VERSION ""

NS_ :

BS_:

BU_: Tester RearECU MyECU

BO_ 3221225472 VECTOR__INDEPENDENT_SIG_MSG: 0 Vector__XXX
 SG_ Signal_TxMulti_Stat : 0|5@1+ (1,0) [0|31] "" Vector__XXX
 SG_ SigTx_Prof1C_DataId_LoByte : 0|8@1+ (1,0) [0|255] "" Vector__XXX
 SG_ SigRx_Prof1C_DataId_LoByte : 0|8@1+ (1,0) [0|255] "" Vector__XXX

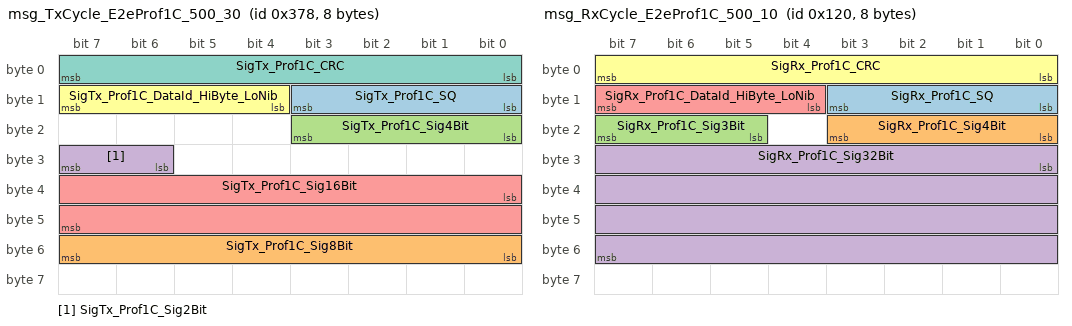
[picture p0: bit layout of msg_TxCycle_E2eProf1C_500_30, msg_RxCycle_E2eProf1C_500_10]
BO_ 888 msg_TxCycle_E2eProf1C_500_30: 8 MyECU
 SG_ SigTx_Prof1C_SQ : 8|4@1+ (1,0) [0|15] ""  RearECU
 SG_ SigTx_Prof1C_Sig8Bit : 48|8@1+ (1,0) [0|255] ""  RearECU
 SG_ SigTx_Prof1C_Sig4Bit : 16|4@1+ (1,0) [0|15] ""  RearECU
 SG_ SigTx_Prof1C_Sig2Bit : 30|2@1+ (1,0) [0|3] ""  RearECU
 SG_ SigTx_Prof1C_Sig16Bit : 32|16@1+ (1,0) [0|65535] ""  RearECU
 SG_ SigTx_Prof1C_DataId_HiByte_LoNib : 12|4@1+ (1,0) [0|15] ""  RearECU
 SG_ SigTx_Prof1C_CRC : 0|8@1+ (1,0) [0|255] ""  RearECU

BO_ 288 msg_RxCycle_E2eProf1C_500_10: 8 RearECU
 SG_ SigRx_Prof1C_SQ : 8|4@1+ (1,0) [0|15] ""  MyECU
 SG_ SigRx_Prof1C_Sig4Bit : 16|4@1+ (1,0) [0|15] ""  MyECU
 SG_ SigRx_Prof1C_Sig3Bit : 21|3@1+ (1,0) [0|7] ""  MyECU
 SG_ SigRx_Prof1C_Sig32Bit : 24|32@1+ (1,0) [0|4294967295] ""  MyECU
 SG_ SigRx_Prof1C_DataId_HiByte_LoNib : 12|4@1+ (1,0) [0|15] ""  MyECU
 SG_ SigRx_Prof1C_CRC : 0|8@1+ (1,0) [0|255] ""  MyECU

BO_ 512 msg_TxCycle100_20: 8 MyECU
 SG_ Signal_SwitchRearInteriorLight : 0|8@1+ (1,0) [0|255] ""  RearECU

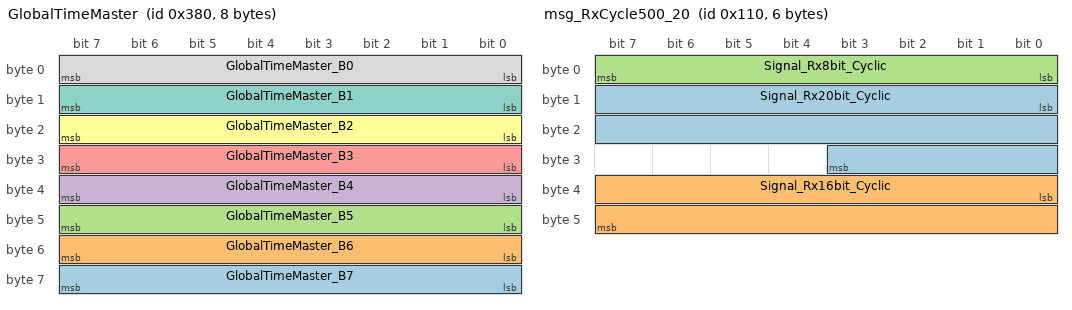
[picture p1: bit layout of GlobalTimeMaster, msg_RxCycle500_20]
BO_ 896 GlobalTimeMaster: 8 RearECU
 SG_ GlobalTimeMaster_B7 : 56|8@1+ (1,0) [0|0] ""  MyECU
 SG_ GlobalTimeMaster_B6 : 48|8@1+ (1,0) [0|0] ""  MyECU
 SG_ GlobalTimeMaster_B5 : 40|8@1+ (1,0) [0|0] ""  MyECU
 SG_ GlobalTimeMaster_B4 : 32|8@1+ (1,0) [0|0] ""  MyECU
 SG_ GlobalTimeMaster_B3 : 24|8@1+ (1,0) [0|0] ""  MyECU
 SG_ GlobalTimeMaster_B2 : 16|8@1+ (1,0) [0|0] ""  MyECU
 SG_ GlobalTimeMaster_B1 : 8|8@1+ (1,0) [0|0] ""  MyECU
 SG_ GlobalTimeMaster_B0 : 0|8@1+ (1,0) [0|0] ""  MyECU

BO_ 263 msg_RxMux: 4 RearECU
 SG_ Signal_RxMultiplexor M : 0|3@1+ (1,0) [0|7] ""  MyECU
 SG_ Signal_RxMulti1_2 m1 : 20|6@1+ (1,0) [0|63] ""  MyECU
 SG_ Signal_RxMulti1_1 m1 : 8|12@1+ (1,0) [0|4095] ""  MyECU
 SG_ Signal_RxMulti1_0 m1 : 4|4@1+ (1,0) [0|15] ""  MyECU
 SG_ Signal_RxMulti0_2 m0 : 7|1@1+ (1,0) [0|1] ""  MyECU
 SG_ Signal_RxMulti0_1 m0 : 8|16@1+ (1,0) [0|65535] ""  MyECU
 SG_ Signal_RxMulti0_0 m0 : 4|3@1+ (1,0) [0|7] ""  MyECU

BO_ 261 msg_TxMux: 6 MyECU
 SG_ Signal_TxMultiplexor M : 0|3@1+ (1,0) [0|7] ""  RearECU
 SG_ Signal_TxMulti0_0 m0 : 22|2@1+ (1,0) [0|3] ""  RearECU
 SG_ Signal_TxMulti1_4 m1 : 32|8@1+ (1,0) [0|255] ""  RearECU
 SG_ Signal_TxMulti1_3 m1 : 40|8@1+ (1,0) [0|255] ""  RearECU
 SG_ Signal_TxMulti1_2 m1 : 24|8@1+ (1,0) [0|255] ""  RearECU
 SG_ Signal_TxMulti1_1 m1 : 16|8@1+ (1,0) [0|255] ""  RearECU
 SG_ Signal_TxMulti1_0 m1 : 8|8@1+ (1,0) [0|255] ""  RearECU
 SG_ Signal_TxMulti0_3 m0 : 24|8@1+ (1,0) [0|255] ""  RearECU
 SG_ Signal_TxMulti0_2 m0 : 16|4@1+ (1,0) [0|15] ""  RearECU
 SG_ Signal_TxMulti0_1 m0 : 8|8@1+ (1,0) [0|255] ""  RearECU

BO_ 360 msg_TxEvent_10: 7 MyECU
 SG_ Signal_Tx24bit_OnWrite : 32|24@1+ (1,0) [0|16777215] ""  RearECU
 SG_ Signal_Tx32bit_OnWrite : 0|32@1+ (1,0) [0|4294967295] ""  RearECU

BO_ 784 msg_RxEvent_20: 4 RearECU
 SG_ Signal_Rx15bit_OnWrite : 12|15@1+ (1,0) [0|32767] ""  MyECU
 SG_ Signal_Rx11bit_OnWrite : 0|11@1+ (1,0) [0|2047] ""  MyECU

BO_ 872 msg_TxCycle1000_10: 2 MyECU
 SG_ Signal_Tx4bit_Cyclic : 10|4@1+ (1,0) [0|15] ""  RearECU
 SG_ Signal_Tx10bit_Cyclic : 0|10@1+ (1,0) [0|1023] ""  RearECU

BO_ 272 msg_RxCycle500_20: 6 RearECU
 SG_ Signal_Rx20bit_Cyclic : 8|20@1+ (1,0) [0|1048575] ""  MyECU
 SG_ Signal_Rx16bit_Cyclic : 32|16@1+ (1,0) [0|65535] ""  MyECU
 SG_ Signal_Rx8bit_Cyclic : 0|8@1+ (1,0) [0|255] ""  MyECU

BO_ 1796 msg_XCP_Response: 8 MyECU
 SG_ Signal_XCP_Response : 0|64@1+ (1,0) [0|1.844674407371E+019] ""  RearECU

BO_ 1795 msg_XCP_Request: 8 RearECU
 SG_ Signal_XCP_Request : 0|64@1+ (1,0) [0|1.844674407371E+019] ""  MyECU

BO_ 616 msg_TxCycle10_0: 7 MyECU
 SG_ Signal_Tx24bit_Cyclic : 32|24@1+ (1,0) [0|16777215] ""  RearECU
 SG_ Signal_Tx32bit_Cyclic : 0|32@1+ (1,0) [0|4294967295] ""  RearECU

BO_ 1558 msg_diag_Uudt_Response_MyECU: 8 MyECU
 SG_ Signal_DiagPeriodicResp : 0|64@1+ (1,0) [0|0] ""  Tester

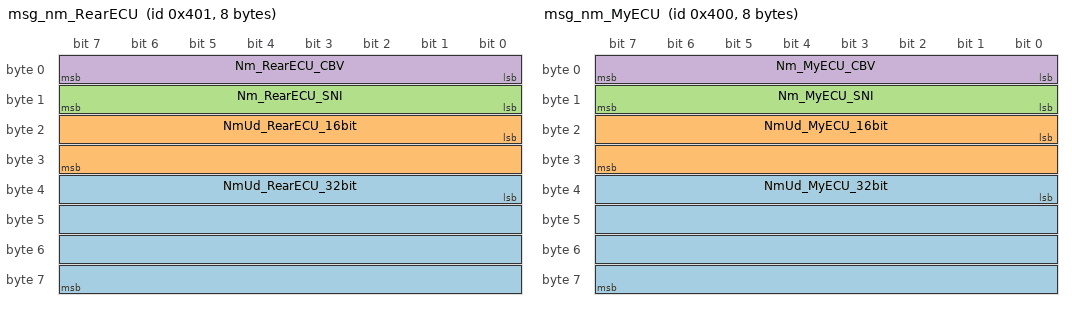
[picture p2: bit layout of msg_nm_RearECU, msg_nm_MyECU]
BO_ 1025 msg_nm_RearECU: 8 RearECU
 SG_ NmUd_RearECU_32bit : 32|32@1+ (1,0) [0|4294967295] ""  MyECU
 SG_ NmUd_RearECU_16bit : 16|16@1+ (1,0) [0|65535] ""  MyECU
 SG_ Nm_RearECU_SNI : 8|8@1+ (1,0) [0|255] ""  MyECU
 SG_ Nm_RearECU_CBV : 0|8@1+ (1,0) [0|255] ""  MyECU

BO_ 1024 msg_nm_MyECU: 8 MyECU
 SG_ NmUd_MyECU_32bit : 32|32@1+ (1,0) [0|4294967295] ""  RearECU
 SG_ NmUd_MyECU_16bit : 16|16@1+ (1,0) [0|65535] ""  RearECU
 SG_ Nm_MyECU_SNI : 8|8@1+ (1,0) [0|255] ""  RearECU
 SG_ Nm_MyECU_CBV : 0|8@1+ (1,0) [0|255] ""  RearECU

BO_ 1554 msg_diag_Response_MyECU: 8 MyECU
 SG_ Signal_DiagResponseMyECU : 0|64@1+ (1,0) [0|1.8446744074E+019] ""  Tester

BO_ 1552 msg_diag_Request_MyECU: 8 Tester
 SG_ Signal_DiagRequestMyECU : 0|64@1+ (1,0) [0|1.8446744074E+019] ""  MyECU

BO_ 1556 msg_diag_RequestGlobal: 8 Tester
 SG_ Signal_DiagRequestGlobal : 0|64@1+ (1,0) [0|1.8446744074E+019] ""  MyECU

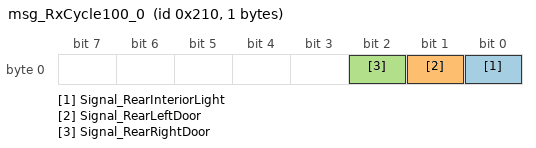
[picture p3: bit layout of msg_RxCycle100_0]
BO_ 528 msg_RxCycle100_0: 1 RearECU
 SG_ Signal_RearInteriorLight : 0|1@1+ (1,0) [0|1] ""  MyECU
 SG_ Signal_RearLeftDoor : 1|1@1+ (1,0) [0|1] ""  MyECU
 SG_ Signal_RearRightDoor : 2|1@1+ (1,0) [0|1] ""  MyECU

CM_ BO_ 3221225472 "This is a message for not used signals, created by Vector CANdb++ DBC OLE DB Provider.";
BA_DEF_  "DBName" STRING ;
BA_DEF_ BO_  "DiagConnection" INT 0 65535;
BA_DEF_ BO_  "DiagUUDTResponse" ENUM  "No","Yes";
BA_DEF_ BO_  "GenMsgStartDelayTime" INT 0 0;
BA_DEF_ BO_  "GenMsgDelayTime" INT 0 0;
BA_DEF_ BO_  "GenMsgNrOfRepetition" INT 0 0;
BA_DEF_ BO_  "GenMsgCycleTimeFast" INT 0 0;
BA_DEF_ BO_  "GenMsgCycleTime" INT 0 0;
BA_DEF_ BO_  "GenMsgSendType" ENUM  "Cyclic","NotUsed","NotUsed","NotUsed","NotUsed","NotUsed","NotUsed","IfActive","NoMsgSendType","NotUsed";
BA_DEF_ SG_  "GenSigStartValue" INT 0 0;
BA_DEF_ SG_  "GenSigCycleTimeActive" INT 0 0;
BA_DEF_ SG_  "GenSigCycleTime" INT 0 0;
BA_DEF_ SG_  "GenSigSendType" ENUM  "Cyclic","OnWrite","OnWriteWithRepetition","OnChange","OnChangeWithRepetition","IfActive","IfActiveWithRepetition","NoSigSendType","OnChangeAndIfActive","OnChangeAndIfActiveWithRepetition";
BA_DEF_  "Baudrate" INT 0 1000000;
BA_DEF_  "BusType" STRING ;
BA_DEF_  "NmType" STRING ;
BA_DEF_  "Manufacturer" STRING ;
BA_DEF_  "NmAsrWaitBusSleepTime" INT 0 65535;
BA_DEF_  "NmAsrTimeoutTime" INT 0 65535;
BA_DEF_  "NmAsrRepeatMessageTime" INT 0 65535;
BA_DEF_ BU_  "NmAsrNodeIdentifier" INT 0 255;
BA_DEF_ BU_  "NmAsrNode" ENUM  "no","yes";
BA_DEF_  "NmAsrMessageCount" INT 0 256;
BA_DEF_ BO_  "NmAsrMessage" ENUM  "no","yes";
BA_DEF_ BU_  "NmAsrCanMsgReducedTime" INT 0 65535;
BA_DEF_  "NmAsrCanMsgCycleTime" INT 0 65535;
BA_DEF_  "NmAsrBaseAddress" HEX 0 65535;
BA_DEF_ BU_  "ILUsed" ENUM  "no","yes";
BA_DEF_ BO_  "GenMsgILSupport" ENUM  "no","yes";
BA_DEF_ BO_  "DiagState" ENUM  "No","Yes";
BA_DEF_ BO_  "DiagResponse" ENUM  "No","Yes";
BA_DEF_ BO_  "DiagRequest" ENUM  "No","Yes";
BA_DEF_DEF_  "DBName" "CAN";
BA_DEF_DEF_  "DiagConnection" 0;
BA_DEF_DEF_  "DiagUUDTResponse" "No";
BA_DEF_DEF_  "GenMsgStartDelayTime" 0;
BA_DEF_DEF_  "GenMsgDelayTime" 0;
BA_DEF_DEF_  "GenMsgNrOfRepetition" 0;
BA_DEF_DEF_  "GenMsgCycleTimeFast" 0;
BA_DEF_DEF_  "GenMsgCycleTime" 0;
BA_DEF_DEF_  "GenMsgSendType" "NoMsgSendType";
BA_DEF_DEF_  "GenSigStartValue" 0;
BA_DEF_DEF_  "GenSigCycleTimeActive" 0;
BA_DEF_DEF_  "GenSigCycleTime" 0;
BA_DEF_DEF_  "GenSigSendType" "Cyclic";
BA_DEF_DEF_  "Baudrate" 500000;
BA_DEF_DEF_  "BusType" "";
BA_DEF_DEF_  "NmType" "";
BA_DEF_DEF_  "Manufacturer" "Vector";
BA_DEF_DEF_  "NmAsrWaitBusSleepTime" 750;
BA_DEF_DEF_  "NmAsrTimeoutTime" 1000;
BA_DEF_DEF_  "NmAsrRepeatMessageTime" 400;
BA_DEF_DEF_  "NmAsrNodeIdentifier" 0;
BA_DEF_DEF_  "NmAsrNode" "yes";
BA_DEF_DEF_  "NmAsrMessageCount" 64;
BA_DEF_DEF_  "NmAsrMessage" "no";
BA_DEF_DEF_  "NmAsrCanMsgReducedTime" 50;
BA_DEF_DEF_  "NmAsrCanMsgCycleTime" 100;
BA_DEF_DEF_  "NmAsrBaseAddress" 1024;
BA_DEF_DEF_  "ILUsed" "yes";
BA_DEF_DEF_  "GenMsgILSupport" "yes";
BA_DEF_DEF_  "DiagState" "No";
BA_DEF_DEF_  "DiagResponse" "No";
BA_DEF_DEF_  "DiagRequest" "No";
BA_ "NmType" "NmAsr";
BA_ "BusType" "CAN";
BA_ "NmAsrNode" BU_ Tester 0;
BA_ "NmAsrNodeIdentifier" BU_ RearECU 1;
BA_ "GenMsgSendType" BO_ 888 0;
BA_ "GenMsgCycleTime" BO_ 888 500;
BA_ "GenMsgStartDelayTime" BO_ 888 30;
BA_ "GenMsgSendType" BO_ 288 0;
BA_ "GenMsgCycleTime" BO_ 288 500;
BA_ "GenMsgStartDelayTime" BO_ 288 10;
BA_ "GenMsgCycleTime" BO_ 512 20;
BA_ "GenMsgILSupport" BO_ 896 0;
BA_ "GenMsgCycleTime" BO_ 263 400;
BA_ "GenMsgSendType" BO_ 263 0;
BA_ "GenMsgCycleTime" BO_ 261 250;
BA_ "GenMsgSendType" BO_ 261 0;
BA_ "GenMsgStartDelayTime" BO_ 360 10;
BA_ "GenMsgStartDelayTime" BO_ 784 20;
BA_ "GenMsgCycleTime" BO_ 872 1000;
BA_ "GenMsgSendType" BO_ 872 0;
BA_ "GenMsgStartDelayTime" BO_ 872 10;
BA_ "GenMsgCycleTime" BO_ 272 500;
BA_ "GenMsgSendType" BO_ 272 0;
BA_ "GenMsgStartDelayTime" BO_ 272 20;
BA_ "GenMsgILSupport" BO_ 1796 0;
BA_ "GenMsgILSupport" BO_ 1795 0;
BA_ "GenMsgSendType" BO_ 616 0;
BA_ "GenMsgCycleTime" BO_ 616 10;
BA_ "DiagUUDTResponse" BO_ 1558 1;
BA_ "GenMsgILSupport" BO_ 1558 0;
BA_ "DiagConnection" BO_ 1558 57345;
BA_ "GenMsgILSupport" BO_ 1025 0;
BA_ "NmAsrMessage" BO_ 1025 1;
BA_ "GenMsgSendType" BO_ 1025 0;
BA_ "GenMsgCycleTime" BO_ 1025 100;
BA_ "GenMsgILSupport" BO_ 1024 0;
BA_ "NmAsrMessage" BO_ 1024 1;
BA_ "GenMsgSendType" BO_ 1024 0;
BA_ "GenMsgCycleTime" BO_ 1024 100;
BA_ "DiagConnection" BO_ 1554 57345;
BA_ "DiagResponse" BO_ 1554 1;
BA_ "GenMsgILSupport" BO_ 1554 0;
BA_ "GenMsgSendType" BO_ 1554 0;
BA_ "GenMsgCycleTime" BO_ 1554 100;
BA_ "DiagConnection" BO_ 1552 57345;
BA_ "DiagRequest" BO_ 1552 1;
BA_ "GenMsgILSupport" BO_ 1552 0;
BA_ "GenMsgSendType" BO_ 1552 0;
BA_ "GenMsgCycleTime" BO_ 1552 100;
BA_ "DiagConnection" BO_ 1556 57344;
BA_ "DiagState" BO_ 1556 1;
BA_ "GenMsgILSupport" BO_ 1556 0;
BA_ "GenMsgSendType" BO_ 1556 0;
BA_ "GenMsgCycleTime" BO_ 1556 100;
BA_ "GenMsgSendType" BO_ 528 0;
BA_ "GenMsgCycleTime" BO_ 528 100;
BA_ "GenSigCycleTime" SG_ 3221225472 Signal_TxMulti_Stat 100;
BA_ "GenSigCycleTimeActive" SG_ 512 Signal_SwitchRearInteriorLight 100;
BA_ "GenSigCycleTime" SG_ 512 Signal_SwitchRearInteriorLight 100;
BA_ "GenSigCycleTime" SG_ 263 Signal_RxMultiplexor 100;
BA_ "GenSigCycleTime" SG_ 263 Signal_RxMulti1_2 100;
BA_ "GenSigStartValue" SG_ 263 Signal_RxMulti1_2 9;
BA_ "GenSigCycleTime" SG_ 263 Signal_RxMulti1_1 100;
BA_ "GenSigStartValue" SG_ 263 Signal_RxMulti1_1 12;
BA_ "GenSigCycleTime" SG_ 263 Signal_RxMulti1_0 100;
BA_ "GenSigCycleTime" SG_ 263 Signal_RxMulti0_2 100;
BA_ "GenSigCycleTime" SG_ 263 Signal_RxMulti0_1 100;
BA_ "GenSigStartValue" SG_ 263 Signal_RxMulti0_1 3;
BA_ "GenSigCycleTime" SG_ 263 Signal_RxMulti0_0 100;
BA_ "GenSigStartValue" SG_ 263 Signal_RxMulti0_0 1;
BA_ "GenSigCycleTime" SG_ 261 Signal_TxMultiplexor 100;
BA_ "GenSigCycleTime" SG_ 261 Signal_TxMulti0_0 100;
BA_ "GenSigCycleTime" SG_ 261 Signal_TxMulti1_4 100;
BA_ "GenSigStartValue" SG_ 261 Signal_TxMulti1_4 20;
BA_ "GenSigCycleTime" SG_ 261 Signal_TxMulti1_3 100;
BA_ "GenSigStartValue" SG_ 261 Signal_TxMulti1_3 19;
BA_ "GenSigCycleTime" SG_ 261 Signal_TxMulti1_2 100;
BA_ "GenSigStartValue" SG_ 261 Signal_TxMulti1_2 18;
BA_ "GenSigCycleTime" SG_ 261 Signal_TxMulti1_1 100;
BA_ "GenSigStartValue" SG_ 261 Signal_TxMulti1_1 17;
BA_ "GenSigCycleTime" SG_ 261 Signal_TxMulti1_0 100;
BA_ "GenSigStartValue" SG_ 261 Signal_TxMulti1_0 16;
BA_ "GenSigCycleTime" SG_ 261 Signal_TxMulti0_3 100;
BA_ "GenSigStartValue" SG_ 261 Signal_TxMulti0_3 3;
BA_ "GenSigCycleTime" SG_ 261 Signal_TxMulti0_2 100;
BA_ "GenSigStartValue" SG_ 261 Signal_TxMulti0_2 2;
BA_ "GenSigCycleTime" SG_ 261 Signal_TxMulti0_1 100;
BA_ "GenSigStartValue" SG_ 261 Signal_TxMulti0_1 1;
BA_ "GenSigSendType" SG_ 360 Signal_Tx24bit_OnWrite 1;
BA_ "GenSigStartValue" SG_ 360 Signal_Tx24bit_OnWrite 63;
BA_ "GenSigSendType" SG_ 360 Signal_Tx32bit_OnWrite 1;
BA_ "GenSigStartValue" SG_ 360 Signal_Tx32bit_OnWrite 31;
BA_ "GenSigSendType" SG_ 784 Signal_Rx15bit_OnWrite 1;
BA_ "GenSigStartValue" SG_ 784 Signal_Rx15bit_OnWrite 25;
BA_ "GenSigSendType" SG_ 784 Signal_Rx11bit_OnWrite 1;
BA_ "GenSigStartValue" SG_ 784 Signal_Rx11bit_OnWrite 50;
BA_ "GenSigCycleTime" SG_ 872 Signal_Tx4bit_Cyclic 1000;
BA_ "GenSigCycleTime" SG_ 872 Signal_Tx10bit_Cyclic 1000;
BA_ "GenSigStartValue" SG_ 272 Signal_Rx20bit_Cyclic 1;
BA_ "GenSigStartValue" SG_ 272 Signal_Rx16bit_Cyclic 32768;
BA_ "GenSigStartValue" SG_ 272 Signal_Rx8bit_Cyclic 15;
BA_ "GenSigSendType" SG_ 1796 Signal_XCP_Response 7;
BA_ "GenSigSendType" SG_ 1795 Signal_XCP_Request 7;
BA_ "GenSigCycleTime" SG_ 616 Signal_Tx24bit_Cyclic 10;
BA_ "GenSigCycleTime" SG_ 616 Signal_Tx32bit_Cyclic 10;
BA_ "GenSigSendType" SG_ 1558 Signal_DiagPeriodicResp 7;
BA_ "GenSigCycleTimeActive" SG_ 1025 NmUd_RearECU_32bit 100;
BA_ "GenSigCycleTime" SG_ 1025 NmUd_RearECU_32bit 100;
BA_ "GenSigCycleTimeActive" SG_ 1025 NmUd_RearECU_16bit 100;
BA_ "GenSigCycleTime" SG_ 1025 NmUd_RearECU_16bit 100;
BA_ "GenSigCycleTimeActive" SG_ 1025 Nm_RearECU_SNI 100;
BA_ "GenSigCycleTime" SG_ 1025 Nm_RearECU_SNI 100;
BA_ "GenSigCycleTimeActive" SG_ 1025 Nm_RearECU_CBV 100;
BA_ "GenSigCycleTime" SG_ 1025 Nm_RearECU_CBV 100;
BA_ "GenSigCycleTimeActive" SG_ 1024 NmUd_MyECU_32bit 100;
BA_ "GenSigCycleTime" SG_ 1024 NmUd_MyECU_32bit 100;
BA_ "GenSigCycleTimeActive" SG_ 1024 NmUd_MyECU_16bit 100;
BA_ "GenSigCycleTime" SG_ 1024 NmUd_MyECU_16bit 100;
BA_ "GenSigCycleTimeActive" SG_ 1024 Nm_MyECU_SNI 100;
BA_ "GenSigCycleTime" SG_ 1024 Nm_MyECU_SNI 100;
BA_ "GenSigCycleTime" SG_ 1024 Nm_MyECU_CBV 100;
BA_ "GenSigCycleTimeActive" SG_ 1024 Nm_MyECU_CBV 100;
BA_ "GenSigSendType" SG_ 1554 Signal_DiagResponseMyECU 7;
BA_ "GenSigSendType" SG_ 1552 Signal_DiagRequestMyECU 7;
BA_ "GenSigSendType" SG_ 1556 Signal_DiagRequestGlobal 7;
BA_ "GenSigCycleTime" SG_ 528 Signal_RearInteriorLight 100;
BA_ "GenSigCycleTimeActive" SG_ 528 Signal_RearInteriorLight 100;
BA_ "GenSigCycleTime" SG_ 528 Signal_RearLeftDoor 100;
BA_ "GenSigCycleTimeActive" SG_ 528 Signal_RearLeftDoor 100;
BA_ "GenSigCycleTime" SG_ 528 Signal_RearRightDoor 100;
BA_ "GenSigCycleTimeActive" SG_ 528 Signal_RearRightDoor 100;
SIG_GROUP_ 888 SgTx_Prof1C_TxCycle 1 : SigTx_Prof1C_CRC SigTx_Prof1C_Sig8Bit SigTx_Prof1C_Sig16Bit SigTx_Prof1C_Sig2Bit SigTx_Prof1C_Sig4Bit SigTx_Prof1C_DataId_HiByte_LoNib SigTx_Prof1C_SQ;
SIG_GROUP_ 288 RgRx_Prof1C_RxCycle 1 : SigRx_Prof1C_Sig32Bit SigRx_Prof1C_Sig3Bit SigRx_Prof1C_Sig4Bit SigRx_Prof1C_DataId_HiByte_LoNib SigRx_Prof1C_SQ SigRx_Prof1C_CRC;
